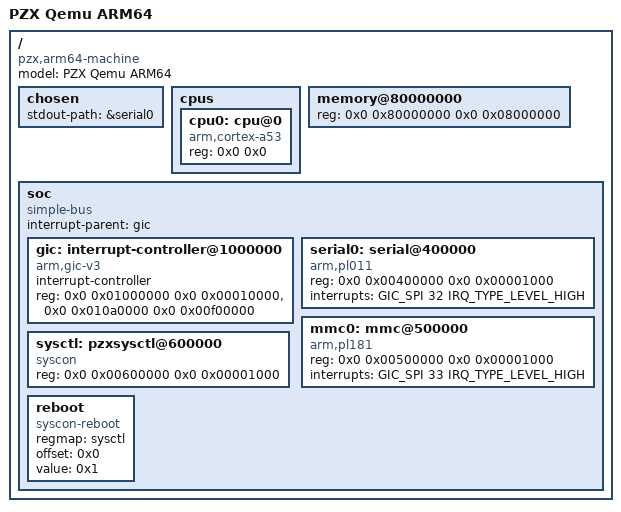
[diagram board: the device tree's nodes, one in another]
// SPDX-License-Identifier: GPL-2.0+

/dts-v1/;

#include <dt-bindings/interrupt-controller/arm-gic.h>

/ {
	model = "PZX Qemu ARM64";
	compatible = "pzx,arm64-machine";
	#address-cells = <2>;
	#size-cells = <2>;

	chosen {
		stdout-path = &serial0;
	};

	cpus {
		#address-cells = <2>;
		#size-cells = <0>;

		cpu0: cpu@0 {
			device_type = "cpu";
			compatible = "arm,cortex-a53";
			reg = <0x0 0x0>;
		};
	};

	memory@80000000 {
		device_type = "memory";
		reg = <0x0 0x80000000 0x0 0x08000000>; /* 128MB DRAM */
	};

	soc {
		compatible = "simple-bus";
		#address-cells = <2>;
		#size-cells = <2>;
		ranges;
		interrupt-parent = <&gic>;

		gic: interrupt-controller@1000000 {
			compatible = "arm,gic-v3";
			#interrupt-cells = <3>;
			interrupt-controller;
			reg = <0x0 0x01000000 0x0 0x00010000>, /* GICD */
			      <0x0 0x010a0000 0x0 0x00f00000>; /* GICR */
		};

		serial0: serial@400000 {
			compatible = "arm,pl011", "arm,primecell";
			reg = <0x0 0x00400000 0x0 0x00001000>;
			interrupts = <GIC_SPI 32 IRQ_TYPE_LEVEL_HIGH>;
		};

		mmc0: mmc@500000 {
			compatible = "arm,pl181", "arm,primecell";
			reg = <0x0 0x00500000 0x0 0x00001000>;
			interrupts = <GIC_SPI 33 IRQ_TYPE_LEVEL_HIGH>;
		};

		sysctl: pzxsysctl@600000 {
			compatible = "syscon", "simple-mfd";
			reg = <0x0 0x00600000 0x0 0x00001000>;
		};

		reboot {
			compatible = "syscon-reboot";
			regmap = <&sysctl>;
			offset = <0x0>;
			value = <0x1>;
		};
	};
};
